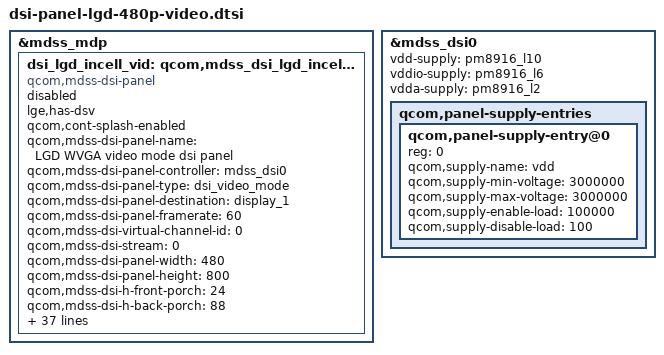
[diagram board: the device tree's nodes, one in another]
&mdss_mdp {
	dsi_lgd_incell_vid: qcom,mdss_dsi_lgd_incell_video{
		lge,has-dsv;
		compatible = "qcom,mdss-dsi-panel";
		status = "disable";
		qcom,cont-splash-enabled;
		qcom,mdss-dsi-panel-name = "LGD WVGA video mode dsi panel";
		qcom,mdss-dsi-panel-controller = <&mdss_dsi0>;
		qcom,mdss-dsi-panel-type = "dsi_video_mode";
		qcom,mdss-dsi-panel-destination = "display_1";
		qcom,mdss-dsi-panel-framerate = <60>;
		qcom,mdss-dsi-virtual-channel-id = <0>;
		qcom,mdss-dsi-stream = <0>;
		qcom,mdss-dsi-panel-width = <480>;
		qcom,mdss-dsi-panel-height = <800>;
		qcom,mdss-dsi-h-front-porch = <24>;
		qcom,mdss-dsi-h-back-porch = <88>;
		qcom,mdss-dsi-h-pulse-width = <8>;
		qcom,mdss-dsi-h-sync-skew = <0>;
		qcom,mdss-dsi-v-back-porch = <12>;
		qcom,mdss-dsi-v-front-porch = <1050>;
		qcom,mdss-dsi-v-pulse-width = <4>;
		qcom,mdss-dsi-h-left-border = <0>;
		qcom,mdss-dsi-h-right-border = <0>;
		qcom,mdss-dsi-v-top-border = <0>;
		qcom,mdss-dsi-v-bottom-border = <0>;
		qcom,mdss-pan-physical-width-dimension = < 59 >;
		qcom,mdss-pan-physical-height-dimension = < 98 >;
		qcom,mdss-dsi-bpp = <24>;
		qcom,mdss-dsi-color-order = "rgb_swap_rgb";
		qcom,mdss-dsi-underflow-color = <0xff>;
		qcom,mdss-dsi-border-color = <0>;
		qcom,mdss-dsi-on-command = [
			39 01 00 00 00 00 08
			B7 00 1B 1B 1B 1B 1B 1B
			39 01 00 00 00 00 07
			B6 06 0A 34 23 41 0A
			39 01 00 00 00 00 05
			B8 00 42 12 F7

			15 01 00 00 00 00 02
			B0 00
			15 01 00 00 00 00 02
			55 00

			39 01 00 00 00 00 0B
			B5 43 A0 01 12 06 00 00 00 00 48
			39 01 00 00 00 00 07
			B4 01 0D 02 02 02 02

			15 01 00 00 00 00 02
			B2 00
			39 01 00 00 00 00 05
			B1 C6 1E 0F 00
			39 01 00 00 00 00 04
			B9 00 03 04
			15 01 00 00 00 00 02
			BB 24

			15 01 00 00 00 00 02
			36 00

			39 01 00 00 00 00 02
			D9 A0
			39 01 00 00 00 00 03
			F8 00 06
			39 01 00 00 00 00 03
			D7 00 B6
			39 01 00 00 00 00 03
			BD 00 23

			39 01 00 00 00 00 0A
			D0 00 26 74 14 00 00 32 03 03
			39 01 00 00 00 00 0A
			D1 00 26 74 14 00 00 32 03 03
			39 01 00 00 00 00 0A
			D2 00 26 74 14 00 00 32 03 03
			39 01 00 00 00 00 0A
			D3 00 26 74 14 00 00 32 03 03
			39 01 00 00 00 00 0A
			D4 00 26 74 14 00 00 32 03 03
			39 01 00 00 00 00 0A
			D5 00 26 74 14 00 00 32 03 03

			/* Image Enhancer for Sharpen */
			39 01 00 00 00 00 04
			61 18 34 00
			/* Image Enhancer for Contrast */
			39 01 00 00 00 00 04
			62 3F 30 FF
			/* Prefer Color Compensation */
			39 01 00 00 00 00 02
			63 00
			39 01 00 00 00 00 1D
			64 81 7F 81 7F 7F 4D AD 85 6A
			99 9B 8C 7D 41 97 5F 64 22 6E
			19 44 69 B0 9C 7D 41 A5 5F
		];
		lge,display-on-cmds = [
			39 01 00 00 00 00 02
			FE 00
			05 01 00 00 78 00 02
			11 00
			05 01 00 00 00 00 02
			29 00
		];
		qcom,mdss-dsi-off-command = [
			05 01 00 00 64 00 02
			10 00
			39 01 00 00 00 00 02
			FE 05
			39 01 00 00 00 00 03
			D8 10 00
		];
		qcom,mdss-dsi-on-command-state = "dsi_lp_mode";
		qcom,mdss-dsi-off-command-state = "dsi_hs_mode";
		qcom,mdss-dsi-h-sync-pulse = <0>;
		qcom,mdss-dsi-traffic-mode = "non_burst_sync_event";
		qcom,mdss-dsi-lane-map = "lane_map_0123";
		//qcom,mdss-dsi-hfp-power-mode;
		//qcom,mdss-dsi-hbp-power-mode;
		//qcom,mdss-dsi-hsa-power-mode;
		qcom,mdss-dsi-bllp-eof-power-mode;
		//qcom,mdss-dsi-bllp-power-mode;
		qcom,mdss-dsi-lane-0-state;
		qcom,mdss-dsi-lane-1-state;
		qcom,mdss-dsi-panel-timings = [D5 32 22 00 60 64 26 36 29 03 04 00];
		qcom,mdss-dsi-t-clk-post = <0x03>;
		qcom,mdss-dsi-t-clk-pre = <0x28>;
		//qcom,mdss-dsi-bl-min-level = <1>;
		//qcom,mdss-dsi-bl-max-level = <4095>;
		qcom,mdss-dsi-dma-trigger = "trigger_sw";
		qcom,mdss-dsi-mdp-trigger = "none";
		//qcom,mdss-dsi-bl-pmic-control-type = "bl_ctrl_wled";
		qcom,mdss-dsi-reset-sequence = <1 20>, <0 20>, <1 20>;
	};
};

&mdss_dsi0 {
	vdd-supply = <&pm8916_l10>;
	vddio-supply = <&pm8916_l6>;
	vdda-supply = <&pm8916_l2>;
	qcom,panel-supply-entries {
		qcom,panel-supply-entry@0 {
			reg = <0>;
			qcom,supply-name = "vdd";
			qcom,supply-min-voltage = <3000000>;
			qcom,supply-max-voltage = <3000000>;
			qcom,supply-enable-load = <100000>;
			qcom,supply-disable-load = <100>;

		};
	};
};

